AUTOSAR XML (schema 4-2-2)
package /SensorActuator_DIO_Test
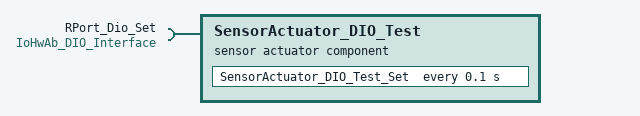
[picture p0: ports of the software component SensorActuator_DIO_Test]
  sensor actuator sw component type SensorActuator_DIO_Test
    require port RPort_Dio_Set: required-interface=IoHwAb_DIO_Interface
    behavior IB_SensorActuator_DIO_Test
      timing event TimingEvent_0: start-on-event=SensorActuator_DIO_Test_Set, period=0.1
      runnable SensorActuator_DIO_Test_Set: symbol=SensorActuator_DIO_Test_Set_Func
        sync call SynchronousServerCallPoint_0: operation=RPort_Dio_Set.Dio_Write
